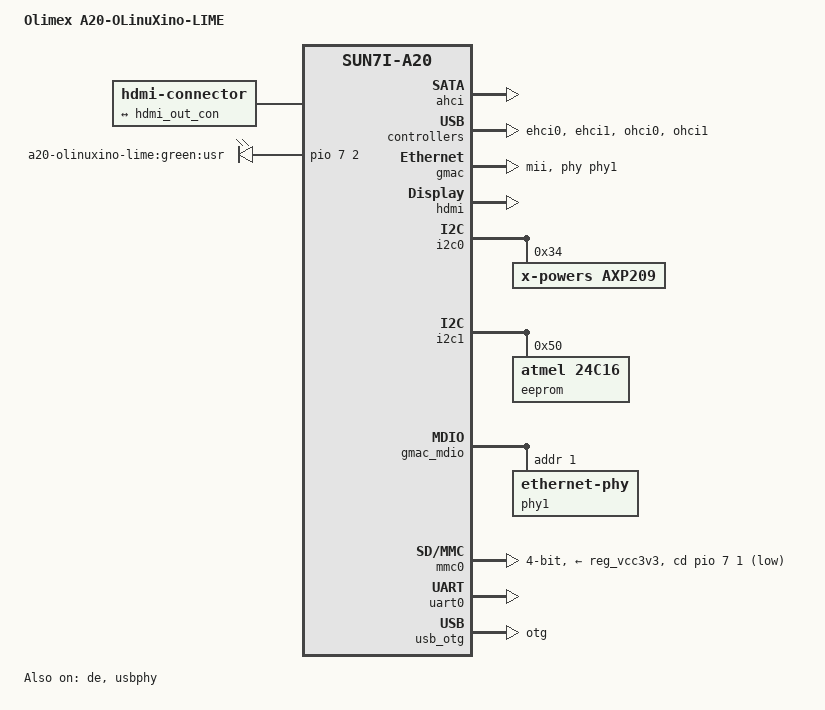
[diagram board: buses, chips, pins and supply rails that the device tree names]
/dts-v1/;
#include "sun7i-a20.dtsi"
#include "sunxi-common-regulators.dtsi"
#include <dt-bindings/gpio/gpio.h>
#include <dt-bindings/interrupt-controller/irq.h>
/ {
	model = "Olimex A20-OLinuXino-LIME";
	compatible = "olimex,a20-olinuxino-lime", "allwinner,sun7i-a20";
	aliases {
		serial0 = &uart0;
	};
	chosen {
		stdout-path = "serial0:115200n8";
	};
	hdmi-connector {
		compatible = "hdmi-connector";
		type = "a";
		port {
			hdmi_con_in: endpoint {
				remote-endpoint = <&hdmi_out_con>;
			};
		};
	};
	leds {
		compatible = "gpio-leds";
		pinctrl-names = "default";
		pinctrl-0 = <&led_pins_olinuxinolime>;
		led {
			label = "a20-olinuxino-lime:green:usr";
			gpios = <&pio 7 2 GPIO_ACTIVE_HIGH>;
			default-state = "on";
		};
	};
};
&ahci {
	target-supply = <&reg_ahci_5v>;
	status = "okay";
};
&de {
	status = "okay";
};
&ehci0 {
	status = "okay";
};
&ehci1 {
	status = "okay";
};
&gmac {
	pinctrl-names = "default";
	pinctrl-0 = <&gmac_mii_pins>;
	phy-handle = <&phy1>;
	phy-mode = "mii";
	status = "okay";
};
&hdmi {
	status = "okay";
};
&hdmi_out {
	hdmi_out_con: endpoint {
		remote-endpoint = <&hdmi_con_in>;
	};
};
&i2c0 {
	status = "okay";
	axp209: pmic@34 {
		compatible = "x-powers,axp209";
		reg = <0x34>;
		interrupt-parent = <&nmi_intc>;
		interrupts = <0 IRQ_TYPE_LEVEL_LOW>;
		interrupt-controller;
		#interrupt-cells = <1>;
	};
};
&i2c1 {
	status = "okay";
	eeprom: eeprom@50 {
		compatible = "atmel,24c16";
		reg = <0x50>;
		pagesize = <16>;
	};
};
&gmac_mdio {
	phy1: ethernet-phy@1 {
		reg = <1>;
	};
};
&mmc0 {
	vmmc-supply = <&reg_vcc3v3>;
	bus-width = <4>;
	cd-gpios = <&pio 7 1 GPIO_ACTIVE_LOW>;  
	status = "okay";
};
&ohci0 {
	status = "okay";
};
&ohci1 {
	status = "okay";
};
&otg_sram {
	status = "okay";
};
&pio {
	led_pins_olinuxinolime: led-pins {
		pins = "PH2";
		function = "gpio_out";
		drive-strength = <20>;
	};
};
&reg_ahci_5v {
	gpio = <&pio 2 3 GPIO_ACTIVE_HIGH>;
	status = "okay";
};
&reg_usb0_vbus {
	status = "okay";
};
&reg_usb1_vbus {
	status = "okay";
};
&reg_usb2_vbus {
	status = "okay";
};
&uart0 {
	pinctrl-names = "default";
	pinctrl-0 = <&uart0_pb_pins>;
	status = "okay";
};
&usb_otg {
	dr_mode = "otg";
	status = "okay";
};
&usbphy {
	usb0_id_det-gpios = <&pio 7 4 (GPIO_ACTIVE_HIGH | GPIO_PULL_UP)>;  
	usb0_vbus_det-gpios = <&pio 7 5 (GPIO_ACTIVE_HIGH | GPIO_PULL_DOWN)>;  
	usb0_vbus-supply = <&reg_usb0_vbus>;
	usb1_vbus-supply = <&reg_usb1_vbus>;
	usb2_vbus-supply = <&reg_usb2_vbus>;
	status = "okay";
};
